# CTRL_MODULE_CORE register map
Vendor: Texas Instruments
Registers are 32-bit, access per field, reset 0x0 unless marked. A register's access mark holds for its fields unless they carry their own. Offsets are as the file gives them; [hi:lo] are bit positions; {n}, {i} and the like mark numbered series; 'fields as' and 'values as' point back to an identical list.

## CTRL_MODULE_CORE (part 10 of 12)
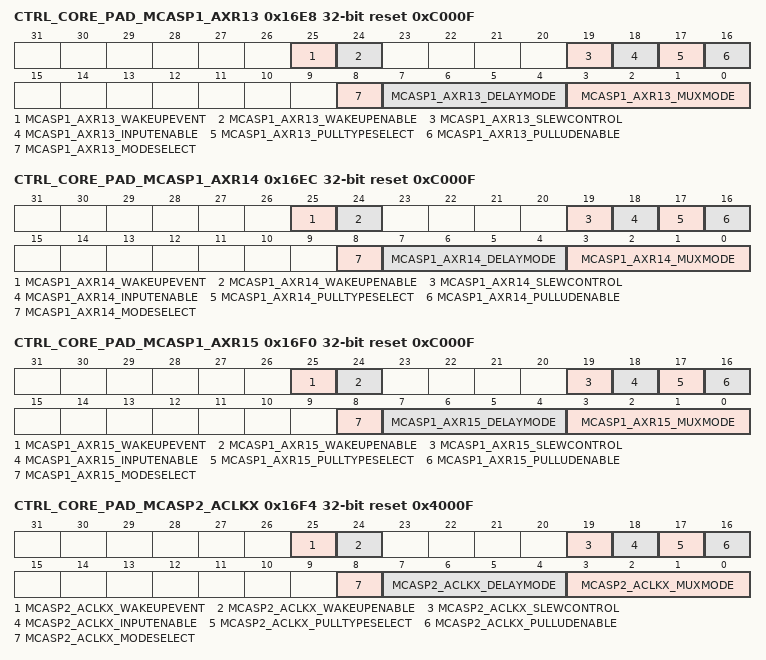
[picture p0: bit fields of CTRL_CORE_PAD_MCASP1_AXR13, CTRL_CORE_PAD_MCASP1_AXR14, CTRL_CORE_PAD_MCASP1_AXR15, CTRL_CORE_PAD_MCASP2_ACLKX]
0x16E8 CTRL_CORE_PAD_MCASP1_AXR13 reset 0xC000F
  [25] MCASP1_AXR13_WAKEUPEVENT ro
    0=NOWAKEUP (No wakeup event detected); 1=WAKEUP (Wakeup event detected)
  [24] MCASP1_AXR13_WAKEUPENABLE rw
    0=DISABLE (Wakeup is disabled); 1=ENABLE (Wakeup is enabled)
  [19] MCASP1_AXR13_SLEWCONTROL rw
    0=FAST_SLEW (Fast slew is selected); 1=SLOW_SLEW (Slow slew is selected)
  [18] MCASP1_AXR13_INPUTENABLE rw
    0=DISABLE (Receive mode is disabled); 1=ENABLE (Receive mode is enabled)
  [17] MCASP1_AXR13_PULLTYPESELECT rw
    0=PULL_DOWN (Pull Down is selected); 1=PULL_UP (Pull Up is selected)
  [16] MCASP1_AXR13_PULLUDENABLE rw
    0=ENABLE (Enables weak Pull Up/Down); 1=DISABLE (Disables weak Pull Up/Down)
  [8] MCASP1_AXR13_MODESELECT rw — Selects between the Default IO Timing Mode and a Virtual or Manual IO Timing Mode. Refer to the device Data Manual for definition of the required settings for a given mode of operation. When this bit is 0b1, a Virtual IO Timing Mode can be selected via the DELAYMODE field of this register, as described in, Virtual IO Timing Modes. Manual IO Timing Modes are selected via the procedure described in , Manual IO Timing Modes.
    0=MUX_MODE (Default IO Timing Mode is used); 1=DELAY_MODE (A Virtual or Manual IO Timing Mode is used)
  [7:4] MCASP1_AXR13_DELAYMODE rw — This bit field selects the Virtual Timing Mode used when the MODESELECT bit is set to 0b1. See, Virtual IO Timing Modes for details.
  [3:0] MCASP1_AXR13_MUXMODE rw
    0=MCASP1_AXR13; 1=MCASP7_AXR1; 7=VIN6A_D10; 10=TIMER10; 11=PR2_MII_MR0_CLK; 12=PR2_PRU1_GPI15; 13=PR2_PRU1_GPO15; 14=GPIO6_4; 15=DRIVER OFF
0x16EC CTRL_CORE_PAD_MCASP1_AXR14 reset 0xC000F
  [25] MCASP1_AXR14_WAKEUPEVENT ro
    values as CTRL_CORE_PAD_MCASP1_AXR13.MCASP1_AXR13_WAKEUPEVENT
  [24] MCASP1_AXR14_WAKEUPENABLE rw
    0=DISABLE (Wakeup is disabled); 1=ENABLE (Wakeup is enabled)
  [19] MCASP1_AXR14_SLEWCONTROL rw
    values as CTRL_CORE_PAD_MCASP1_AXR13.MCASP1_AXR13_SLEWCONTROL
  [18] MCASP1_AXR14_INPUTENABLE rw
    values as CTRL_CORE_PAD_MCASP1_AXR13.MCASP1_AXR13_INPUTENABLE
  [17] MCASP1_AXR14_PULLTYPESELECT rw
    values as CTRL_CORE_PAD_MCASP1_AXR13.MCASP1_AXR13_PULLTYPESELECT
  [16] MCASP1_AXR14_PULLUDENABLE rw
    values as CTRL_CORE_PAD_MCASP1_AXR13.MCASP1_AXR13_PULLUDENABLE
  [8] MCASP1_AXR14_MODESELECT rw — Selects between the Default IO Timing Mode and a Virtual or Manual IO Timing Mode. Refer to the device Data Manual for definition of the required settings for a given mode of operation. When this bit is 0b1, a Virtual IO Timing Mode can be selected via the DELAYMODE field of this register, as described in, Virtual IO Timing Modes. Manual IO Timing Modes are selected via the procedure described in , Manual IO Timing Modes.
    values as CTRL_CORE_PAD_MCASP1_AXR13.MCASP1_AXR13_MODESELECT
  [7:4] MCASP1_AXR14_DELAYMODE rw — This bit field selects the Virtual Timing Mode used when the MODESELECT bit is set to 0b1. See, Virtual IO Timing Modes for details.
  [3:0] MCASP1_AXR14_MUXMODE rw
    0=MCASP1_AXR14; 1=MCASP7_ACLKX; 2=MCASP7_ACLKR; 7=VIN6A_D9; 10=TIMER11; 11=PR2_MII0_RXDV; 12=PR2_PRU1_GPI16; 13=PR2_PRU1_GPO16; 14=GPIO6_5; 15=DRIVER OFF
0x16F0 CTRL_CORE_PAD_MCASP1_AXR15 reset 0xC000F
  [25] MCASP1_AXR15_WAKEUPEVENT ro
    values as CTRL_CORE_PAD_MCASP1_AXR13.MCASP1_AXR13_WAKEUPEVENT
  [24] MCASP1_AXR15_WAKEUPENABLE rw
    0=DISABLE (Wakeup is disabled); 1=ENABLE (Wakeup is enabled)
  [19] MCASP1_AXR15_SLEWCONTROL rw
    values as CTRL_CORE_PAD_MCASP1_AXR13.MCASP1_AXR13_SLEWCONTROL
  [18] MCASP1_AXR15_INPUTENABLE rw
    values as CTRL_CORE_PAD_MCASP1_AXR13.MCASP1_AXR13_INPUTENABLE
  [17] MCASP1_AXR15_PULLTYPESELECT rw
    values as CTRL_CORE_PAD_MCASP1_AXR13.MCASP1_AXR13_PULLTYPESELECT
  [16] MCASP1_AXR15_PULLUDENABLE rw
    values as CTRL_CORE_PAD_MCASP1_AXR13.MCASP1_AXR13_PULLUDENABLE
  [8] MCASP1_AXR15_MODESELECT rw — Selects between the Default IO Timing Mode and a Virtual or Manual IO Timing Mode. Refer to the device Data Manual for definition of the required settings for a given mode of operation. When this bit is 0b1, a Virtual IO Timing Mode can be selected via the DELAYMODE field of this register, as described in, Virtual IO Timing Modes. Manual IO Timing Modes are selected via the procedure described in , Manual IO Timing Modes.
    values as CTRL_CORE_PAD_MCASP1_AXR13.MCASP1_AXR13_MODESELECT
  [7:4] MCASP1_AXR15_DELAYMODE rw — This bit field selects the Virtual Timing Mode used when the MODESELECT bit is set to 0b1. See, Virtual IO Timing Modes for details.
  [3:0] MCASP1_AXR15_MUXMODE rw
    0=MCASP1_AXR15; 1=MCASP7_FSX; 2=MCASP7_FSR; 7=VIN6A_D8; 10=TIMER12; 11=PR2_MII0_RXD3; 12=PR2_PRU0_GPI20; 13=PR2_PRU0_GPO20; 14=GPIO6_6; 15=DRIVER OFF
0x16F4 CTRL_CORE_PAD_MCASP2_ACLKX reset 0x4000F
  [25] MCASP2_ACLKX_WAKEUPEVENT ro
    values as CTRL_CORE_PAD_MCASP1_AXR13.MCASP1_AXR13_WAKEUPEVENT
  [24] MCASP2_ACLKX_WAKEUPENABLE rw
    0=DISABLE (Wakeup is disabled); 1=ENABLE (Wakeup is enabled)
  [19] MCASP2_ACLKX_SLEWCONTROL rw
    values as CTRL_CORE_PAD_MCASP1_AXR13.MCASP1_AXR13_SLEWCONTROL
  [18] MCASP2_ACLKX_INPUTENABLE rw
    values as CTRL_CORE_PAD_MCASP1_AXR13.MCASP1_AXR13_INPUTENABLE
  [17] MCASP2_ACLKX_PULLTYPESELECT rw
    values as CTRL_CORE_PAD_MCASP1_AXR13.MCASP1_AXR13_PULLTYPESELECT
  [16] MCASP2_ACLKX_PULLUDENABLE rw
    values as CTRL_CORE_PAD_MCASP1_AXR13.MCASP1_AXR13_PULLUDENABLE
  [8] MCASP2_ACLKX_MODESELECT rw — Selects between the Default IO Timing Mode and a Virtual or Manual IO Timing Mode. Refer to the device Data Manual for definition of the required settings for a given mode of operation. When this bit is 0b1, a Virtual IO Timing Mode can be selected via the DELAYMODE field of this register, as described in, Virtual IO Timing Modes. Manual IO Timing Modes are selected via the procedure described in , Manual IO Timing Modes.
    values as CTRL_CORE_PAD_MCASP1_AXR13.MCASP1_AXR13_MODESELECT
  [7:4] MCASP2_ACLKX_DELAYMODE rw — This bit field selects the Virtual Timing Mode used when the MODESELECT bit is set to 0b1. See, Virtual IO Timing Modes for details.
  [3:0] MCASP2_ACLKX_MUXMODE rw
    0=MCASP2_ACLKX; 7=VIN6A_D7; 11=PR2_MII0_RXD2; 12=PR2_PRU0_GPI18; 13=PR2_PRU0_GPO18; 15=DRIVER OFF
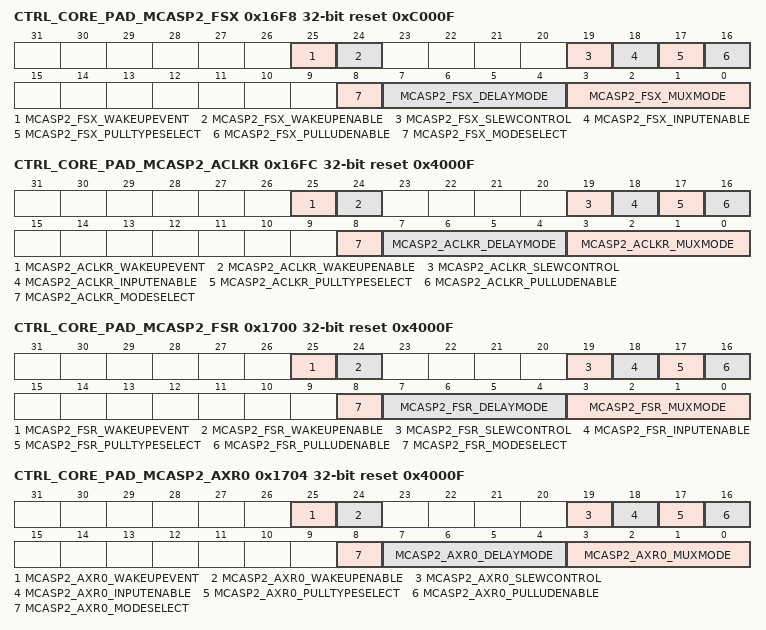
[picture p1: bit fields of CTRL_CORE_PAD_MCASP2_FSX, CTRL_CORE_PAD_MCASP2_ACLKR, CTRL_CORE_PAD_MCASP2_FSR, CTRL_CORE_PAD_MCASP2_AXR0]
0x16F8 CTRL_CORE_PAD_MCASP2_FSX reset 0xC000F
  [25] MCASP2_FSX_WAKEUPEVENT ro
    values as CTRL_CORE_PAD_MCASP1_AXR13.MCASP1_AXR13_WAKEUPEVENT
  [24] MCASP2_FSX_WAKEUPENABLE rw
    0=DISABLE (Wakeup is disabled); 1=ENABLE (Wakeup is enabled)
  [19] MCASP2_FSX_SLEWCONTROL rw
    values as CTRL_CORE_PAD_MCASP1_AXR13.MCASP1_AXR13_SLEWCONTROL
  [18] MCASP2_FSX_INPUTENABLE rw
    values as CTRL_CORE_PAD_MCASP1_AXR13.MCASP1_AXR13_INPUTENABLE
  [17] MCASP2_FSX_PULLTYPESELECT rw
    values as CTRL_CORE_PAD_MCASP1_AXR13.MCASP1_AXR13_PULLTYPESELECT
  [16] MCASP2_FSX_PULLUDENABLE rw
    values as CTRL_CORE_PAD_MCASP1_AXR13.MCASP1_AXR13_PULLUDENABLE
  [8] MCASP2_FSX_MODESELECT rw — Selects between the Default IO Timing Mode and a Virtual or Manual IO Timing Mode. Refer to the device Data Manual for definition of the required settings for a given mode of operation. When this bit is 0b1, a Virtual IO Timing Mode can be selected via the DELAYMODE field of this register, as described in, Virtual IO Timing Modes. Manual IO Timing Modes are selected via the procedure described in , Manual IO Timing Modes.
    values as CTRL_CORE_PAD_MCASP1_AXR13.MCASP1_AXR13_MODESELECT
  [7:4] MCASP2_FSX_DELAYMODE rw — This bit field selects the Virtual Timing Mode used when the MODESELECT bit is set to 0b1. See, Virtual IO Timing Modes for details.
  [3:0] MCASP2_FSX_MUXMODE rw
    0=MCASP2_FSX; 7=VIN6A_D6; 11=PR2_MII0_RXD1; 12=PR2_PRU0_GPI19; 13=PR2_PRU0_GPO19; 15=DRIVER OFF
0x16FC CTRL_CORE_PAD_MCASP2_ACLKR reset 0x4000F
  [25] MCASP2_ACLKR_WAKEUPEVENT ro
    values as CTRL_CORE_PAD_MCASP1_AXR13.MCASP1_AXR13_WAKEUPEVENT
  [24] MCASP2_ACLKR_WAKEUPENABLE rw
    0=DISABLE (Wakeup is disabled); 1=ENABLE (Wakeup is enabled)
  [19] MCASP2_ACLKR_SLEWCONTROL rw
    values as CTRL_CORE_PAD_MCASP1_AXR13.MCASP1_AXR13_SLEWCONTROL
  [18] MCASP2_ACLKR_INPUTENABLE rw
    values as CTRL_CORE_PAD_MCASP1_AXR13.MCASP1_AXR13_INPUTENABLE
  [17] MCASP2_ACLKR_PULLTYPESELECT rw
    values as CTRL_CORE_PAD_MCASP1_AXR13.MCASP1_AXR13_PULLTYPESELECT
  [16] MCASP2_ACLKR_PULLUDENABLE rw
    values as CTRL_CORE_PAD_MCASP1_AXR13.MCASP1_AXR13_PULLUDENABLE
  [8] MCASP2_ACLKR_MODESELECT rw — Selects between the Default IO Timing Mode and a Virtual or Manual IO Timing Mode. Refer to the device Data Manual for definition of the required settings for a given mode of operation. When this bit is 0b1, a Virtual IO Timing Mode can be selected via the DELAYMODE field of this register, as described in, Virtual IO Timing Modes. Manual IO Timing Modes are selected via the procedure described in , Manual IO Timing Modes.
    values as CTRL_CORE_PAD_MCASP1_AXR13.MCASP1_AXR13_MODESELECT
  [7:4] MCASP2_ACLKR_DELAYMODE rw — This bit field selects the Virtual Timing Mode used when the MODESELECT bit is set to 0b1. See, Virtual IO Timing Modes for details.
  [3:0] MCASP2_ACLKR_MUXMODE rw
    0=MCASP2_ACLKR; 1=MCASP8_AXR2; 6=VOUT2_D8; 8=VIN4A_D8; 15=DRIVER OFF
0x1700 CTRL_CORE_PAD_MCASP2_FSR reset 0x4000F
  [25] MCASP2_FSR_WAKEUPEVENT ro
    values as CTRL_CORE_PAD_MCASP1_AXR13.MCASP1_AXR13_WAKEUPEVENT
  [24] MCASP2_FSR_WAKEUPENABLE rw
    0=DISABLE (Wakeup is disabled); 1=ENABLE (Wakeup is enabled)
  [19] MCASP2_FSR_SLEWCONTROL rw
    values as CTRL_CORE_PAD_MCASP1_AXR13.MCASP1_AXR13_SLEWCONTROL
  [18] MCASP2_FSR_INPUTENABLE rw
    values as CTRL_CORE_PAD_MCASP1_AXR13.MCASP1_AXR13_INPUTENABLE
  [17] MCASP2_FSR_PULLTYPESELECT rw
    values as CTRL_CORE_PAD_MCASP1_AXR13.MCASP1_AXR13_PULLTYPESELECT
  [16] MCASP2_FSR_PULLUDENABLE rw
    values as CTRL_CORE_PAD_MCASP1_AXR13.MCASP1_AXR13_PULLUDENABLE
  [8] MCASP2_FSR_MODESELECT rw — Selects between the Default IO Timing Mode and a Virtual or Manual IO Timing Mode. Refer to the device Data Manual for definition of the required settings for a given mode of operation. When this bit is 0b1, a Virtual IO Timing Mode can be selected via the DELAYMODE field of this register, as described in, Virtual IO Timing Modes. Manual IO Timing Modes are selected via the procedure described in , Manual IO Timing Modes.
    values as CTRL_CORE_PAD_MCASP1_AXR13.MCASP1_AXR13_MODESELECT
  [7:4] MCASP2_FSR_DELAYMODE rw — This bit field selects the Virtual Timing Mode used when the MODESELECT bit is set to 0b1. See, Virtual IO Timing Modes for details.
  [3:0] MCASP2_FSR_MUXMODE rw
    0=MCASP2_FSR; 1=MCASP8_AXR3; 6=VOUT2_D9; 8=VIN4A_D9; 15=DRIVER OFF
0x1704 CTRL_CORE_PAD_MCASP2_AXR0 reset 0x4000F
  [25] MCASP2_AXR0_WAKEUPEVENT ro
    values as CTRL_CORE_PAD_MCASP1_AXR13.MCASP1_AXR13_WAKEUPEVENT
  [24] MCASP2_AXR0_WAKEUPENABLE rw
    0=DISABLE (Wakeup is disabled); 1=ENABLE (Wakeup is enabled)
  [19] MCASP2_AXR0_SLEWCONTROL rw
    values as CTRL_CORE_PAD_MCASP1_AXR13.MCASP1_AXR13_SLEWCONTROL
  [18] MCASP2_AXR0_INPUTENABLE rw
    values as CTRL_CORE_PAD_MCASP1_AXR13.MCASP1_AXR13_INPUTENABLE
  [17] MCASP2_AXR0_PULLTYPESELECT rw
    values as CTRL_CORE_PAD_MCASP1_AXR13.MCASP1_AXR13_PULLTYPESELECT
  [16] MCASP2_AXR0_PULLUDENABLE rw
    values as CTRL_CORE_PAD_MCASP1_AXR13.MCASP1_AXR13_PULLUDENABLE
  [8] MCASP2_AXR0_MODESELECT rw — Selects between the Default IO Timing Mode and a Virtual or Manual IO Timing Mode. Refer to the device Data Manual for definition of the required settings for a given mode of operation. When this bit is 0b1, a Virtual IO Timing Mode can be selected via the DELAYMODE field of this register, as described in, Virtual IO Timing Modes. Manual IO Timing Modes are selected via the procedure described in , Manual IO Timing Modes.
    values as CTRL_CORE_PAD_MCASP1_AXR13.MCASP1_AXR13_MODESELECT
  [7:4] MCASP2_AXR0_DELAYMODE rw — This bit field selects the Virtual Timing Mode used when the MODESELECT bit is set to 0b1. See, Virtual IO Timing Modes for details.
  [3:0] MCASP2_AXR0_MUXMODE rw
    0=MCASP2_AXR0; 6=VOUT2_D10; 8=VIN4A_D10; 15=DRIVER OFF
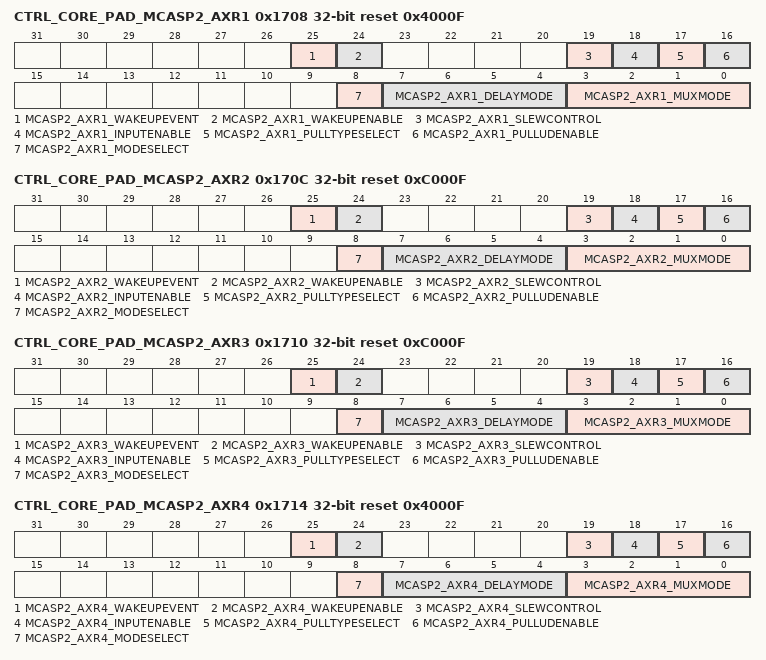
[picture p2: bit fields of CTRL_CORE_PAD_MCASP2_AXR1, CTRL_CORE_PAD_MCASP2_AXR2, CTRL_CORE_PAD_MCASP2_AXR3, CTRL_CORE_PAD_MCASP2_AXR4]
0x1708 CTRL_CORE_PAD_MCASP2_AXR1 reset 0x4000F
  [25] MCASP2_AXR1_WAKEUPEVENT ro
    values as CTRL_CORE_PAD_MCASP1_AXR13.MCASP1_AXR13_WAKEUPEVENT
  [24] MCASP2_AXR1_WAKEUPENABLE rw
    0=DISABLE (Wakeup is disabled); 1=ENABLE (Wakeup is enabled)
  [19] MCASP2_AXR1_SLEWCONTROL rw
    values as CTRL_CORE_PAD_MCASP1_AXR13.MCASP1_AXR13_SLEWCONTROL
  [18] MCASP2_AXR1_INPUTENABLE rw
    values as CTRL_CORE_PAD_MCASP1_AXR13.MCASP1_AXR13_INPUTENABLE
  [17] MCASP2_AXR1_PULLTYPESELECT rw
    values as CTRL_CORE_PAD_MCASP1_AXR13.MCASP1_AXR13_PULLTYPESELECT
  [16] MCASP2_AXR1_PULLUDENABLE rw
    values as CTRL_CORE_PAD_MCASP1_AXR13.MCASP1_AXR13_PULLUDENABLE
  [8] MCASP2_AXR1_MODESELECT rw — Selects between the Default IO Timing Mode and a Virtual or Manual IO Timing Mode. Refer to the device Data Manual for definition of the required settings for a given mode of operation. When this bit is 0b1, a Virtual IO Timing Mode can be selected via the DELAYMODE field of this register, as described in, Virtual IO Timing Modes. Manual IO Timing Modes are selected via the procedure described in , Manual IO Timing Modes.
    values as CTRL_CORE_PAD_MCASP1_AXR13.MCASP1_AXR13_MODESELECT
  [7:4] MCASP2_AXR1_DELAYMODE rw — This bit field selects the Virtual Timing Mode used when the MODESELECT bit is set to 0b1. See, Virtual IO Timing Modes for details.
  [3:0] MCASP2_AXR1_MUXMODE rw
    0=MCASP2_AXR1; 6=VOUT2_D11; 8=VIN4A_D11; 15=DRIVER OFF
0x170C CTRL_CORE_PAD_MCASP2_AXR2 reset 0xC000F
  [25] MCASP2_AXR2_WAKEUPEVENT ro
    values as CTRL_CORE_PAD_MCASP1_AXR13.MCASP1_AXR13_WAKEUPEVENT
  [24] MCASP2_AXR2_WAKEUPENABLE rw
    0=DISABLE (Wakeup is disabled); 1=ENABLE (Wakeup is enabled)
  [19] MCASP2_AXR2_SLEWCONTROL rw
    values as CTRL_CORE_PAD_MCASP1_AXR13.MCASP1_AXR13_SLEWCONTROL
  [18] MCASP2_AXR2_INPUTENABLE rw
    values as CTRL_CORE_PAD_MCASP1_AXR13.MCASP1_AXR13_INPUTENABLE
  [17] MCASP2_AXR2_PULLTYPESELECT rw
    values as CTRL_CORE_PAD_MCASP1_AXR13.MCASP1_AXR13_PULLTYPESELECT
  [16] MCASP2_AXR2_PULLUDENABLE rw
    values as CTRL_CORE_PAD_MCASP1_AXR13.MCASP1_AXR13_PULLUDENABLE
  [8] MCASP2_AXR2_MODESELECT rw — Selects between the Default IO Timing Mode and a Virtual or Manual IO Timing Mode. Refer to the device Data Manual for definition of the required settings for a given mode of operation. When this bit is 0b1, a Virtual IO Timing Mode can be selected via the DELAYMODE field of this register, as described in, Virtual IO Timing Modes. Manual IO Timing Modes are selected via the procedure described in , Manual IO Timing Modes.
    values as CTRL_CORE_PAD_MCASP1_AXR13.MCASP1_AXR13_MODESELECT
  [7:4] MCASP2_AXR2_DELAYMODE rw — This bit field selects the Virtual Timing Mode used when the MODESELECT bit is set to 0b1. See, Virtual IO Timing Modes for details.
  [3:0] MCASP2_AXR2_MUXMODE rw
    0=MCASP2_AXR2; 1=MCASP3_AXR2; 7=VIN6A_D5; 11=PR2_MII0_RXD0; 12=PR2_PRU0_GPI16; 13=PR2_PRU0_GPO16; 14=GPIO6_8; 15=DRIVER OFF
0x1710 CTRL_CORE_PAD_MCASP2_AXR3 reset 0xC000F
  [25] MCASP2_AXR3_WAKEUPEVENT ro
    values as CTRL_CORE_PAD_MCASP1_AXR13.MCASP1_AXR13_WAKEUPEVENT
  [24] MCASP2_AXR3_WAKEUPENABLE rw
    0=DISABLE (Wakeup is disabled); 1=ENABLE (Wakeup is enabled)
  [19] MCASP2_AXR3_SLEWCONTROL rw
    values as CTRL_CORE_PAD_MCASP1_AXR13.MCASP1_AXR13_SLEWCONTROL
  [18] MCASP2_AXR3_INPUTENABLE rw
    values as CTRL_CORE_PAD_MCASP1_AXR13.MCASP1_AXR13_INPUTENABLE
  [17] MCASP2_AXR3_PULLTYPESELECT rw
    values as CTRL_CORE_PAD_MCASP1_AXR13.MCASP1_AXR13_PULLTYPESELECT
  [16] MCASP2_AXR3_PULLUDENABLE rw
    values as CTRL_CORE_PAD_MCASP1_AXR13.MCASP1_AXR13_PULLUDENABLE
  [8] MCASP2_AXR3_MODESELECT rw — Selects between the Default IO Timing Mode and a Virtual or Manual IO Timing Mode. Refer to the device Data Manual for definition of the required settings for a given mode of operation. When this bit is 0b1, a Virtual IO Timing Mode can be selected via the DELAYMODE field of this register, as described in, Virtual IO Timing Modes. Manual IO Timing Modes are selected via the procedure described in , Manual IO Timing Modes.
    values as CTRL_CORE_PAD_MCASP1_AXR13.MCASP1_AXR13_MODESELECT
  [7:4] MCASP2_AXR3_DELAYMODE rw — This bit field selects the Virtual Timing Mode used when the MODESELECT bit is set to 0b1. See, Virtual IO Timing Modes for details.
  [3:0] MCASP2_AXR3_MUXMODE rw
    0=MCASP2_AXR3; 1=MCASP3_AXR3; 7=VIN6A_D4; 11=PR2_MII0_RXLINK; 12=PR2_PRU0_GPI17; 13=PR2_PRU0_GPO17; 14=GPIO6_9; 15=DRIVER OFF
0x1714 CTRL_CORE_PAD_MCASP2_AXR4 reset 0x4000F
  [25] MCASP2_AXR4_WAKEUPEVENT ro
    values as CTRL_CORE_PAD_MCASP1_AXR13.MCASP1_AXR13_WAKEUPEVENT
  [24] MCASP2_AXR4_WAKEUPENABLE rw
    0=DISABLE (Wakeup is disabled); 1=ENABLE (Wakeup is enabled)
  [19] MCASP2_AXR4_SLEWCONTROL rw
    values as CTRL_CORE_PAD_MCASP1_AXR13.MCASP1_AXR13_SLEWCONTROL
  [18] MCASP2_AXR4_INPUTENABLE rw
    values as CTRL_CORE_PAD_MCASP1_AXR13.MCASP1_AXR13_INPUTENABLE
  [17] MCASP2_AXR4_PULLTYPESELECT rw
    values as CTRL_CORE_PAD_MCASP1_AXR13.MCASP1_AXR13_PULLTYPESELECT
  [16] MCASP2_AXR4_PULLUDENABLE rw
    values as CTRL_CORE_PAD_MCASP1_AXR13.MCASP1_AXR13_PULLUDENABLE
  [8] MCASP2_AXR4_MODESELECT rw — Selects between the Default IO Timing Mode and a Virtual or Manual IO Timing Mode. Refer to the device Data Manual for definition of the required settings for a given mode of operation. When this bit is 0b1, a Virtual IO Timing Mode can be selected via the DELAYMODE field of this register, as described in, Virtual IO Timing Modes. Manual IO Timing Modes are selected via the procedure described in , Manual IO Timing Modes.
    values as CTRL_CORE_PAD_MCASP1_AXR13.MCASP1_AXR13_MODESELECT
  [7:4] MCASP2_AXR4_DELAYMODE rw — This bit field selects the Virtual Timing Mode used when the MODESELECT bit is set to 0b1. See, Virtual IO Timing Modes for details.
  [3:0] MCASP2_AXR4_MUXMODE rw
    0=MCASP2_AXR4; 1=MCASP8_AXR0; 6=VOUT2_D12; 8=VIN4A_D12; 14=GPIO1_4; 15=DRIVER OFF
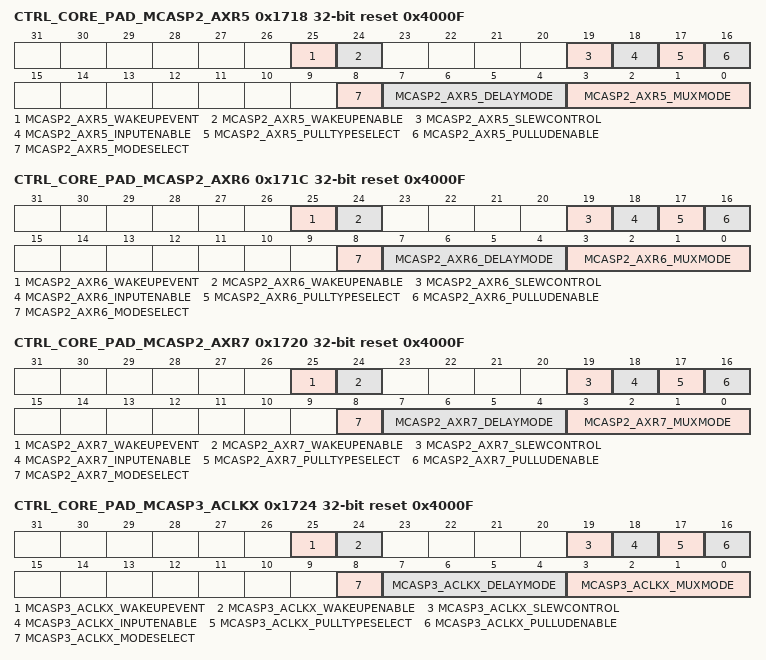
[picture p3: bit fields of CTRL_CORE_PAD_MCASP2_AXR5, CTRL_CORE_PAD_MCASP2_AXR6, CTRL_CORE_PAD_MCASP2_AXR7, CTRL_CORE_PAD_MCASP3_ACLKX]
0x1718 CTRL_CORE_PAD_MCASP2_AXR5 reset 0x4000F
  [25] MCASP2_AXR5_WAKEUPEVENT ro
    values as CTRL_CORE_PAD_MCASP1_AXR13.MCASP1_AXR13_WAKEUPEVENT
  [24] MCASP2_AXR5_WAKEUPENABLE rw
    0=DISABLE (Wakeup is disabled); 1=ENABLE (Wakeup is enabled)
  [19] MCASP2_AXR5_SLEWCONTROL rw
    values as CTRL_CORE_PAD_MCASP1_AXR13.MCASP1_AXR13_SLEWCONTROL
  [18] MCASP2_AXR5_INPUTENABLE rw
    values as CTRL_CORE_PAD_MCASP1_AXR13.MCASP1_AXR13_INPUTENABLE
  [17] MCASP2_AXR5_PULLTYPESELECT rw
    values as CTRL_CORE_PAD_MCASP1_AXR13.MCASP1_AXR13_PULLTYPESELECT
  [16] MCASP2_AXR5_PULLUDENABLE rw
    values as CTRL_CORE_PAD_MCASP1_AXR13.MCASP1_AXR13_PULLUDENABLE
  [8] MCASP2_AXR5_MODESELECT rw — Selects between the Default IO Timing Mode and a Virtual or Manual IO Timing Mode. Refer to the device Data Manual for definition of the required settings for a given mode of operation. When this bit is 0b1, a Virtual IO Timing Mode can be selected via the DELAYMODE field of this register, as described in, Virtual IO Timing Modes. Manual IO Timing Modes are selected via the procedure described in , Manual IO Timing Modes.
    values as CTRL_CORE_PAD_MCASP1_AXR13.MCASP1_AXR13_MODESELECT
  [7:4] MCASP2_AXR5_DELAYMODE rw — This bit field selects the Virtual Timing Mode used when the MODESELECT bit is set to 0b1. See, Virtual IO Timing Modes for details.
  [3:0] MCASP2_AXR5_MUXMODE rw
    0=MCASP2_AXR5; 1=MCASP8_AXR1; 6=VOUT2_D13; 8=VIN4A_D13; 14=GPIO6_7; 15=DRIVER OFF
0x171C CTRL_CORE_PAD_MCASP2_AXR6 reset 0x4000F
  [25] MCASP2_AXR6_WAKEUPEVENT ro
    values as CTRL_CORE_PAD_MCASP1_AXR13.MCASP1_AXR13_WAKEUPEVENT
  [24] MCASP2_AXR6_WAKEUPENABLE rw
    0=DISABLE (Wakeup is disabled); 1=ENABLE (Wakeup is enabled)
  [19] MCASP2_AXR6_SLEWCONTROL rw
    values as CTRL_CORE_PAD_MCASP1_AXR13.MCASP1_AXR13_SLEWCONTROL
  [18] MCASP2_AXR6_INPUTENABLE rw
    values as CTRL_CORE_PAD_MCASP1_AXR13.MCASP1_AXR13_INPUTENABLE
  [17] MCASP2_AXR6_PULLTYPESELECT rw
    values as CTRL_CORE_PAD_MCASP1_AXR13.MCASP1_AXR13_PULLTYPESELECT
  [16] MCASP2_AXR6_PULLUDENABLE rw
    values as CTRL_CORE_PAD_MCASP1_AXR13.MCASP1_AXR13_PULLUDENABLE
  [8] MCASP2_AXR6_MODESELECT rw — Selects between the Default IO Timing Mode and a Virtual or Manual IO Timing Mode. Refer to the device Data Manual for definition of the required settings for a given mode of operation. When this bit is 0b1, a Virtual IO Timing Mode can be selected via the DELAYMODE field of this register, as described in, Virtual IO Timing Modes. Manual IO Timing Modes are selected via the procedure described in , Manual IO Timing Modes.
    values as CTRL_CORE_PAD_MCASP1_AXR13.MCASP1_AXR13_MODESELECT
  [7:4] MCASP2_AXR6_DELAYMODE rw — This bit field selects the Virtual Timing Mode used when the MODESELECT bit is set to 0b1. See, Virtual IO Timing Modes for details.
  [3:0] MCASP2_AXR6_MUXMODE rw
    0=MCASP2_AXR6; 1=MCASP8_ACLKX; 2=MCASP8_ACLKR; 6=VOUT2_D14; 8=VIN4A_D14; 14=GPIO2_29; 15=DRIVER OFF
0x1720 CTRL_CORE_PAD_MCASP2_AXR7 reset 0x4000F
  [25] MCASP2_AXR7_WAKEUPEVENT ro
    values as CTRL_CORE_PAD_MCASP1_AXR13.MCASP1_AXR13_WAKEUPEVENT
  [24] MCASP2_AXR7_WAKEUPENABLE rw
    0=DISABLE (Wakeup is disabled); 1=ENABLE (Wakeup is enabled)
  [19] MCASP2_AXR7_SLEWCONTROL rw
    values as CTRL_CORE_PAD_MCASP1_AXR13.MCASP1_AXR13_SLEWCONTROL
  [18] MCASP2_AXR7_INPUTENABLE rw
    values as CTRL_CORE_PAD_MCASP1_AXR13.MCASP1_AXR13_INPUTENABLE
  [17] MCASP2_AXR7_PULLTYPESELECT rw
    values as CTRL_CORE_PAD_MCASP1_AXR13.MCASP1_AXR13_PULLTYPESELECT
  [16] MCASP2_AXR7_PULLUDENABLE rw
    values as CTRL_CORE_PAD_MCASP1_AXR13.MCASP1_AXR13_PULLUDENABLE
  [8] MCASP2_AXR7_MODESELECT rw — Selects between the Default IO Timing Mode and a Virtual or Manual IO Timing Mode. Refer to the device Data Manual for definition of the required settings for a given mode of operation. When this bit is 0b1, a Virtual IO Timing Mode can be selected via the DELAYMODE field of this register, as described in, Virtual IO Timing Modes. Manual IO Timing Modes are selected via the procedure described in , Manual IO Timing Modes.
    values as CTRL_CORE_PAD_MCASP1_AXR13.MCASP1_AXR13_MODESELECT
  [7:4] MCASP2_AXR7_DELAYMODE rw — This bit field selects the Virtual Timing Mode used when the MODESELECT bit is set to 0b1. See, Virtual IO Timing Modes for details.
  [3:0] MCASP2_AXR7_MUXMODE rw
    0=MCASP2_AXR7; 1=MCASP8_FSX; 2=MCASP8_FSR; 6=VOUT2_D15; 8=VIN4A_D15; 14=GPIO1_5; 15=DRIVER OFF
0x1724 CTRL_CORE_PAD_MCASP3_ACLKX reset 0x4000F
  [25] MCASP3_ACLKX_WAKEUPEVENT ro
    values as CTRL_CORE_PAD_MCASP1_AXR13.MCASP1_AXR13_WAKEUPEVENT
  [24] MCASP3_ACLKX_WAKEUPENABLE rw
    0=DISABLE (Wakeup is disabled); 1=ENABLE (Wakeup is enabled)
  [19] MCASP3_ACLKX_SLEWCONTROL rw
    values as CTRL_CORE_PAD_MCASP1_AXR13.MCASP1_AXR13_SLEWCONTROL
  [18] MCASP3_ACLKX_INPUTENABLE rw
    values as CTRL_CORE_PAD_MCASP1_AXR13.MCASP1_AXR13_INPUTENABLE
  [17] MCASP3_ACLKX_PULLTYPESELECT rw
    values as CTRL_CORE_PAD_MCASP1_AXR13.MCASP1_AXR13_PULLTYPESELECT
  [16] MCASP3_ACLKX_PULLUDENABLE rw
    values as CTRL_CORE_PAD_MCASP1_AXR13.MCASP1_AXR13_PULLUDENABLE
  [8] MCASP3_ACLKX_MODESELECT rw — Selects between the Default IO Timing Mode and a Virtual or Manual IO Timing Mode. Refer to the device Data Manual for definition of the required settings for a given mode of operation. When this bit is 0b1, a Virtual IO Timing Mode can be selected via the DELAYMODE field of this register, as described in, Virtual IO Timing Modes. Manual IO Timing Modes are selected via the procedure described in , Manual IO Timing Modes.
    values as CTRL_CORE_PAD_MCASP1_AXR13.MCASP1_AXR13_MODESELECT
  [7:4] MCASP3_ACLKX_DELAYMODE rw — This bit field selects the Virtual Timing Mode used when the MODESELECT bit is set to 0b1. See, Virtual IO Timing Modes for details.
  [3:0] MCASP3_ACLKX_MUXMODE rw
    0=MCASP3_ACLKX; 1=MCASP3_ACLKR; 2=MCASP2_AXR12; 3=UART7_RXD; 7=VIN6A_D3; 11=PR2_MII0_CRS; 12=PR2_PRU0_GPI12; 13=PR2_PRU0_GPO12; 14=GPIO5_13; 15=DRIVER OFF
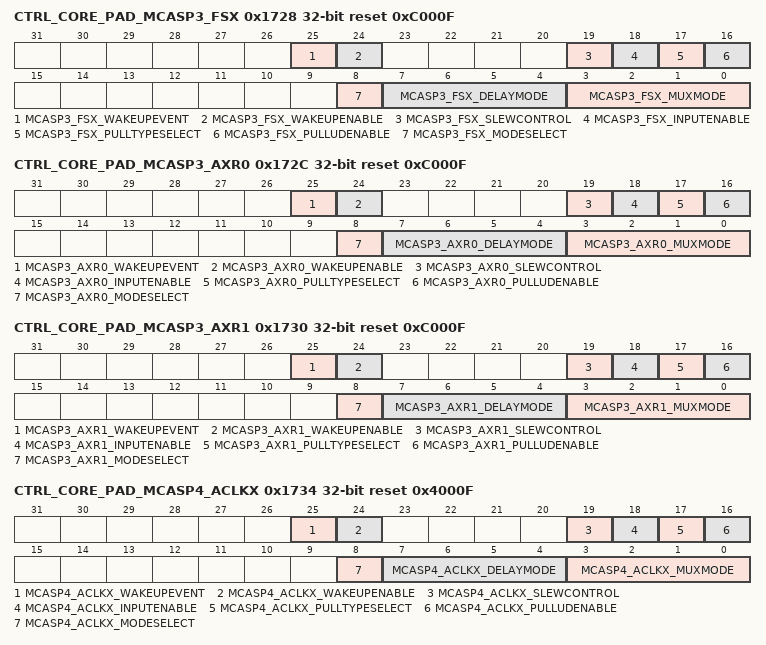
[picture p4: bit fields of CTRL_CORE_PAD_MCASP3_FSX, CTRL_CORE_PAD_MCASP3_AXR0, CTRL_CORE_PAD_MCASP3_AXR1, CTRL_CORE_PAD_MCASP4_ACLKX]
0x1728 CTRL_CORE_PAD_MCASP3_FSX reset 0xC000F
  [25] MCASP3_FSX_WAKEUPEVENT ro
    values as CTRL_CORE_PAD_MCASP1_AXR13.MCASP1_AXR13_WAKEUPEVENT
  [24] MCASP3_FSX_WAKEUPENABLE rw
    0=DISABLE (Wakeup is disabled); 1=ENABLE (Wakeup is enabled)
  [19] MCASP3_FSX_SLEWCONTROL rw
    values as CTRL_CORE_PAD_MCASP1_AXR13.MCASP1_AXR13_SLEWCONTROL
  [18] MCASP3_FSX_INPUTENABLE rw
    values as CTRL_CORE_PAD_MCASP1_AXR13.MCASP1_AXR13_INPUTENABLE
  [17] MCASP3_FSX_PULLTYPESELECT rw
    values as CTRL_CORE_PAD_MCASP1_AXR13.MCASP1_AXR13_PULLTYPESELECT
  [16] MCASP3_FSX_PULLUDENABLE rw
    values as CTRL_CORE_PAD_MCASP1_AXR13.MCASP1_AXR13_PULLUDENABLE
  [8] MCASP3_FSX_MODESELECT rw — Selects between the Default IO Timing Mode and a Virtual or Manual IO Timing Mode. Refer to the device Data Manual for definition of the required settings for a given mode of operation. When this bit is 0b1, a Virtual IO Timing Mode can be selected via the DELAYMODE field of this register, as described in, Virtual IO Timing Modes. Manual IO Timing Modes are selected via the procedure described in , Manual IO Timing Modes.
    values as CTRL_CORE_PAD_MCASP1_AXR13.MCASP1_AXR13_MODESELECT
  [7:4] MCASP3_FSX_DELAYMODE rw — This bit field selects the Virtual Timing Mode used when the MODESELECT bit is set to 0b1. See, Virtual IO Timing Modes for details.
  [3:0] MCASP3_FSX_MUXMODE rw
    0=MCASP3_FSX; 1=MCASP3_FSR; 2=MCASP2_AXR13; 3=UART7_TXD; 7=VIN6A_D2; 11=PR2_MII0_COL; 12=PR2_PRU0_GPI13; 13=PR2_PRU0_GPO13; 14=GPIO5_14; 15=DRIVER OFF
0x172C CTRL_CORE_PAD_MCASP3_AXR0 reset 0xC000F
  [25] MCASP3_AXR0_WAKEUPEVENT ro
    values as CTRL_CORE_PAD_MCASP1_AXR13.MCASP1_AXR13_WAKEUPEVENT
  [24] MCASP3_AXR0_WAKEUPENABLE rw
    0=DISABLE (Wakeup is disabled); 1=ENABLE (Wakeup is enabled)
  [19] MCASP3_AXR0_SLEWCONTROL rw
    values as CTRL_CORE_PAD_MCASP1_AXR13.MCASP1_AXR13_SLEWCONTROL
  [18] MCASP3_AXR0_INPUTENABLE rw
    values as CTRL_CORE_PAD_MCASP1_AXR13.MCASP1_AXR13_INPUTENABLE
  [17] MCASP3_AXR0_PULLTYPESELECT rw
    values as CTRL_CORE_PAD_MCASP1_AXR13.MCASP1_AXR13_PULLTYPESELECT
  [16] MCASP3_AXR0_PULLUDENABLE rw
    values as CTRL_CORE_PAD_MCASP1_AXR13.MCASP1_AXR13_PULLUDENABLE
  [8] MCASP3_AXR0_MODESELECT rw — Selects between the Default IO Timing Mode and a Virtual or Manual IO Timing Mode. Refer to the device Data Manual for definition of the required settings for a given mode of operation. When this bit is 0b1, a Virtual IO Timing Mode can be selected via the DELAYMODE field of this register, as described in, Virtual IO Timing Modes. Manual IO Timing Modes are selected via the procedure described in , Manual IO Timing Modes.
    values as CTRL_CORE_PAD_MCASP1_AXR13.MCASP1_AXR13_MODESELECT
  [7:4] MCASP3_AXR0_DELAYMODE rw — This bit field selects the Virtual Timing Mode used when the MODESELECT bit is set to 0b1. See, Virtual IO Timing Modes for details.
  [3:0] MCASP3_AXR0_MUXMODE rw
    0=MCASP3_AXR0; 2=MCASP2_AXR14; 3=UART7_CTSN; 4=UART5_RXD; 7=VIN6A_D1; 11=PR2_MII1_RXER; 12=PR2_PRU0_GPI14; 13=PR2_PRU0_GPO14; 15=DRIVER OFF
0x1730 CTRL_CORE_PAD_MCASP3_AXR1 reset 0xC000F
  [25] MCASP3_AXR1_WAKEUPEVENT ro
    values as CTRL_CORE_PAD_MCASP1_AXR13.MCASP1_AXR13_WAKEUPEVENT
  [24] MCASP3_AXR1_WAKEUPENABLE rw
    0=DISABLE (Wakeup is disabled); 1=ENABLE (Wakeup is enabled)
  [19] MCASP3_AXR1_SLEWCONTROL rw
    values as CTRL_CORE_PAD_MCASP1_AXR13.MCASP1_AXR13_SLEWCONTROL
  [18] MCASP3_AXR1_INPUTENABLE rw
    values as CTRL_CORE_PAD_MCASP1_AXR13.MCASP1_AXR13_INPUTENABLE
  [17] MCASP3_AXR1_PULLTYPESELECT rw
    values as CTRL_CORE_PAD_MCASP1_AXR13.MCASP1_AXR13_PULLTYPESELECT
  [16] MCASP3_AXR1_PULLUDENABLE rw
    values as CTRL_CORE_PAD_MCASP1_AXR13.MCASP1_AXR13_PULLUDENABLE
  [8] MCASP3_AXR1_MODESELECT rw — Selects between the Default IO Timing Mode and a Virtual or Manual IO Timing Mode. Refer to the device Data Manual for definition of the required settings for a given mode of operation. When this bit is 0b1, a Virtual IO Timing Mode can be selected via the DELAYMODE field of this register, as described in, Virtual IO Timing Modes. Manual IO Timing Modes are selected via the procedure described in , Manual IO Timing Modes.
    values as CTRL_CORE_PAD_MCASP1_AXR13.MCASP1_AXR13_MODESELECT
  [7:4] MCASP3_AXR1_DELAYMODE rw — This bit field selects the Virtual Timing Mode used when the MODESELECT bit is set to 0b1. See, Virtual IO Timing Modes for details.
  [3:0] MCASP3_AXR1_MUXMODE rw
    0=MCASP3_AXR1; 2=MCASP2_AXR15; 3=UART7_RTSN; 4=UART5_TXD; 7=VIN6A_D0; 9=VIN5A_FLD0; 11=PR2_MII1_RXLINK; 12=PR2_PRU0_GPI15; 13=PR2_PRU0_GPO15; 15=DRIVER OFF
0x1734 CTRL_CORE_PAD_MCASP4_ACLKX reset 0x4000F
  [25] MCASP4_ACLKX_WAKEUPEVENT ro
    values as CTRL_CORE_PAD_MCASP1_AXR13.MCASP1_AXR13_WAKEUPEVENT
  [24] MCASP4_ACLKX_WAKEUPENABLE rw
    0=DISABLE (Wakeup is disabled); 1=ENABLE (Wakeup is enabled)
  [19] MCASP4_ACLKX_SLEWCONTROL rw
    values as CTRL_CORE_PAD_MCASP1_AXR13.MCASP1_AXR13_SLEWCONTROL
  [18] MCASP4_ACLKX_INPUTENABLE rw
    values as CTRL_CORE_PAD_MCASP1_AXR13.MCASP1_AXR13_INPUTENABLE
  [17] MCASP4_ACLKX_PULLTYPESELECT rw
    values as CTRL_CORE_PAD_MCASP1_AXR13.MCASP1_AXR13_PULLTYPESELECT
  [16] MCASP4_ACLKX_PULLUDENABLE rw
    values as CTRL_CORE_PAD_MCASP1_AXR13.MCASP1_AXR13_PULLUDENABLE
  [8] MCASP4_ACLKX_MODESELECT rw — Selects between the Default IO Timing Mode and a Virtual or Manual IO Timing Mode. Refer to the device Data Manual for definition of the required settings for a given mode of operation. When this bit is 0b1, a Virtual IO Timing Mode can be selected via the DELAYMODE field of this register, as described in, Virtual IO Timing Modes. Manual IO Timing Modes are selected via the procedure described in , Manual IO Timing Modes.
    values as CTRL_CORE_PAD_MCASP1_AXR13.MCASP1_AXR13_MODESELECT
  [7:4] MCASP4_ACLKX_DELAYMODE rw — This bit field selects the Virtual Timing Mode used when the MODESELECT bit is set to 0b1. See, Virtual IO Timing Modes for details.
  [3:0] MCASP4_ACLKX_MUXMODE rw
    0=MCASP4_ACLKX; 1=MCASP4_ACLKR; 2=SPI3_SCLK; 3=UART8_RXD; 4=I2C4_SDA; 6=VOUT2_D16; 8=VIN4A_D16; 9=VIN5A_D15; 15=DRIVER OFF
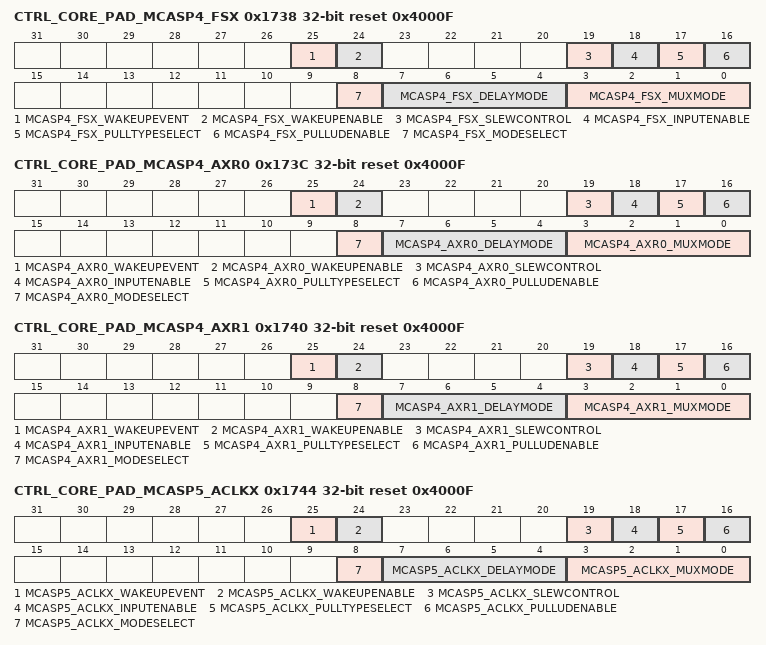
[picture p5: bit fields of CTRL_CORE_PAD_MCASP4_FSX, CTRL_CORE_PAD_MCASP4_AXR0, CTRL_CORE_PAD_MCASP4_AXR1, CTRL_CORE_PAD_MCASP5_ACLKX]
0x1738 CTRL_CORE_PAD_MCASP4_FSX reset 0x4000F
  [25] MCASP4_FSX_WAKEUPEVENT ro
    values as CTRL_CORE_PAD_MCASP1_AXR13.MCASP1_AXR13_WAKEUPEVENT
  [24] MCASP4_FSX_WAKEUPENABLE rw
    0=DISABLE (Wakeup is disabled); 1=ENABLE (Wakeup is enabled)
  [19] MCASP4_FSX_SLEWCONTROL rw
    values as CTRL_CORE_PAD_MCASP1_AXR13.MCASP1_AXR13_SLEWCONTROL
  [18] MCASP4_FSX_INPUTENABLE rw
    values as CTRL_CORE_PAD_MCASP1_AXR13.MCASP1_AXR13_INPUTENABLE
  [17] MCASP4_FSX_PULLTYPESELECT rw
    values as CTRL_CORE_PAD_MCASP1_AXR13.MCASP1_AXR13_PULLTYPESELECT
  [16] MCASP4_FSX_PULLUDENABLE rw
    values as CTRL_CORE_PAD_MCASP1_AXR13.MCASP1_AXR13_PULLUDENABLE
  [8] MCASP4_FSX_MODESELECT rw — Selects between the Default IO Timing Mode and a Virtual or Manual IO Timing Mode. Refer to the device Data Manual for definition of the required settings for a given mode of operation. When this bit is 0b1, a Virtual IO Timing Mode can be selected via the DELAYMODE field of this register, as described in, Virtual IO Timing Modes. Manual IO Timing Modes are selected via the procedure described in , Manual IO Timing Modes.
    values as CTRL_CORE_PAD_MCASP1_AXR13.MCASP1_AXR13_MODESELECT
  [7:4] MCASP4_FSX_DELAYMODE rw — This bit field selects the Virtual Timing Mode used when the MODESELECT bit is set to 0b1. See, Virtual IO Timing Modes for details.
  [3:0] MCASP4_FSX_MUXMODE rw
    0=MCASP4_FSX; 1=MCASP4_FSR; 2=SPI3_D1; 3=UART8_TXD; 4=I2C4_SCL; 6=VOUT2_D17; 8=VIN4A_D17; 9=VIN5A_D14; 15=DRIVER OFF
0x173C CTRL_CORE_PAD_MCASP4_AXR0 reset 0x4000F
  [25] MCASP4_AXR0_WAKEUPEVENT ro
    values as CTRL_CORE_PAD_MCASP1_AXR13.MCASP1_AXR13_WAKEUPEVENT
  [24] MCASP4_AXR0_WAKEUPENABLE rw
    0=DISABLE (Wakeup is disabled); 1=ENABLE (Wakeup is enabled)
  [19] MCASP4_AXR0_SLEWCONTROL rw
    values as CTRL_CORE_PAD_MCASP1_AXR13.MCASP1_AXR13_SLEWCONTROL
  [18] MCASP4_AXR0_INPUTENABLE rw
    values as CTRL_CORE_PAD_MCASP1_AXR13.MCASP1_AXR13_INPUTENABLE
  [17] MCASP4_AXR0_PULLTYPESELECT rw
    values as CTRL_CORE_PAD_MCASP1_AXR13.MCASP1_AXR13_PULLTYPESELECT
  [16] MCASP4_AXR0_PULLUDENABLE rw
    values as CTRL_CORE_PAD_MCASP1_AXR13.MCASP1_AXR13_PULLUDENABLE
  [8] MCASP4_AXR0_MODESELECT rw — Selects between the Default IO Timing Mode and a Virtual or Manual IO Timing Mode. Refer to the device Data Manual for definition of the required settings for a given mode of operation. When this bit is 0b1, a Virtual IO Timing Mode can be selected via the DELAYMODE field of this register, as described in, Virtual IO Timing Modes. Manual IO Timing Modes are selected via the procedure described in , Manual IO Timing Modes.
    values as CTRL_CORE_PAD_MCASP1_AXR13.MCASP1_AXR13_MODESELECT
  [7:4] MCASP4_AXR0_DELAYMODE rw — This bit field selects the Virtual Timing Mode used when the MODESELECT bit is set to 0b1. See, Virtual IO Timing Modes for details.
  [3:0] MCASP4_AXR0_MUXMODE rw
    0=MCASP4_AXR0; 2=SPI3_D0; 3=UART8_CTSN; 4=UART4_RXD; 6=VOUT2_D18; 8=VIN4A_D18; 9=VIN5A_D13; 15=DRIVER OFF
0x1740 CTRL_CORE_PAD_MCASP4_AXR1 reset 0x4000F
  [25] MCASP4_AXR1_WAKEUPEVENT ro
    values as CTRL_CORE_PAD_MCASP1_AXR13.MCASP1_AXR13_WAKEUPEVENT
  [24] MCASP4_AXR1_WAKEUPENABLE rw
    0=DISABLE (Wakeup is disabled); 1=ENABLE (Wakeup is enabled)
  [19] MCASP4_AXR1_SLEWCONTROL rw
    values as CTRL_CORE_PAD_MCASP1_AXR13.MCASP1_AXR13_SLEWCONTROL
  [18] MCASP4_AXR1_INPUTENABLE rw
    values as CTRL_CORE_PAD_MCASP1_AXR13.MCASP1_AXR13_INPUTENABLE
  [17] MCASP4_AXR1_PULLTYPESELECT rw
    values as CTRL_CORE_PAD_MCASP1_AXR13.MCASP1_AXR13_PULLTYPESELECT
  [16] MCASP4_AXR1_PULLUDENABLE rw
    values as CTRL_CORE_PAD_MCASP1_AXR13.MCASP1_AXR13_PULLUDENABLE
  [8] MCASP4_AXR1_MODESELECT rw — Selects between the Default IO Timing Mode and a Virtual or Manual IO Timing Mode. Refer to the device Data Manual for definition of the required settings for a given mode of operation. When this bit is 0b1, a Virtual IO Timing Mode can be selected via the DELAYMODE field of this register, as described in, Virtual IO Timing Modes. Manual IO Timing Modes are selected via the procedure described in , Manual IO Timing Modes.
    values as CTRL_CORE_PAD_MCASP1_AXR13.MCASP1_AXR13_MODESELECT
  [7:4] MCASP4_AXR1_DELAYMODE rw — This bit field selects the Virtual Timing Mode used when the MODESELECT bit is set to 0b1. See, Virtual IO Timing Modes for details.
  [3:0] MCASP4_AXR1_MUXMODE rw
    0=MCASP4_AXR1; 2=SPI3_CS0; 3=UART8_RTSN; 4=UART4_TXD; 6=VOUT2_D19; 8=VIN4A_D19; 9=VIN5A_D12; 12=PR2_PRU1_GPI0; 13=PR2_PRU1_GPO0; 15=DRIVER OFF
0x1744 CTRL_CORE_PAD_MCASP5_ACLKX reset 0x4000F
  [25] MCASP5_ACLKX_WAKEUPEVENT ro
    values as CTRL_CORE_PAD_MCASP1_AXR13.MCASP1_AXR13_WAKEUPEVENT
  [24] MCASP5_ACLKX_WAKEUPENABLE rw
    0=DISABLE (Wakeup is disabled); 1=ENABLE (Wakeup is enabled)
  [19] MCASP5_ACLKX_SLEWCONTROL rw
    values as CTRL_CORE_PAD_MCASP1_AXR13.MCASP1_AXR13_SLEWCONTROL
  [18] MCASP5_ACLKX_INPUTENABLE rw
    values as CTRL_CORE_PAD_MCASP1_AXR13.MCASP1_AXR13_INPUTENABLE
  [17] MCASP5_ACLKX_PULLTYPESELECT rw
    values as CTRL_CORE_PAD_MCASP1_AXR13.MCASP1_AXR13_PULLTYPESELECT
  [16] MCASP5_ACLKX_PULLUDENABLE rw
    values as CTRL_CORE_PAD_MCASP1_AXR13.MCASP1_AXR13_PULLUDENABLE
  [8] MCASP5_ACLKX_MODESELECT rw — Selects between the Default IO Timing Mode and a Virtual or Manual IO Timing Mode. Refer to the device Data Manual for definition of the required settings for a given mode of operation. When this bit is 0b1, a Virtual IO Timing Mode can be selected via the DELAYMODE field of this register, as described in, Virtual IO Timing Modes. Manual IO Timing Modes are selected via the procedure described in , Manual IO Timing Modes.
    values as CTRL_CORE_PAD_MCASP1_AXR13.MCASP1_AXR13_MODESELECT
  [7:4] MCASP5_ACLKX_DELAYMODE rw — This bit field selects the Virtual Timing Mode used when the MODESELECT bit is set to 0b1. See, Virtual IO Timing Modes for details.
  [3:0] MCASP5_ACLKX_MUXMODE rw
    0=MCASP5_ACLKX; 1=MCASP5_ACLKR; 2=SPI4_SCLK; 3=UART9_RXD; 4=I2C5_SDA; 6=VOUT2_D20; 8=VIN4A_D20; 9=VIN5A_D11; 12=PR2_PRU1_GPI1; 13=PR2_PRU1_GPO1; 15=DRIVER OFF
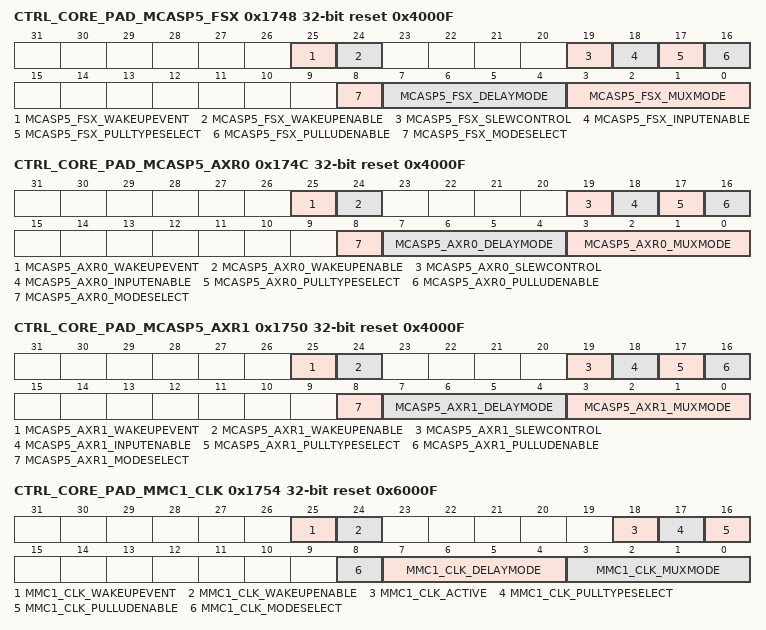
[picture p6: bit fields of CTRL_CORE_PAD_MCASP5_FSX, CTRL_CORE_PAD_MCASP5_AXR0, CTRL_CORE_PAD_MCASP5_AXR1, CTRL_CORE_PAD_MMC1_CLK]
0x1748 CTRL_CORE_PAD_MCASP5_FSX reset 0x4000F
  [25] MCASP5_FSX_WAKEUPEVENT ro
    values as CTRL_CORE_PAD_MCASP1_AXR13.MCASP1_AXR13_WAKEUPEVENT
  [24] MCASP5_FSX_WAKEUPENABLE rw
    0=DISABLE (Wakeup is disabled); 1=ENABLE (Wakeup is enabled)
  [19] MCASP5_FSX_SLEWCONTROL rw
    values as CTRL_CORE_PAD_MCASP1_AXR13.MCASP1_AXR13_SLEWCONTROL
  [18] MCASP5_FSX_INPUTENABLE rw
    values as CTRL_CORE_PAD_MCASP1_AXR13.MCASP1_AXR13_INPUTENABLE
  [17] MCASP5_FSX_PULLTYPESELECT rw
    values as CTRL_CORE_PAD_MCASP1_AXR13.MCASP1_AXR13_PULLTYPESELECT
  [16] MCASP5_FSX_PULLUDENABLE rw
    values as CTRL_CORE_PAD_MCASP1_AXR13.MCASP1_AXR13_PULLUDENABLE
  [8] MCASP5_FSX_MODESELECT rw — Selects between the Default IO Timing Mode and a Virtual or Manual IO Timing Mode. Refer to the device Data Manual for definition of the required settings for a given mode of operation. When this bit is 0b1, a Virtual IO Timing Mode can be selected via the DELAYMODE field of this register, as described in, Virtual IO Timing Modes. Manual IO Timing Modes are selected via the procedure described in , Manual IO Timing Modes.
    values as CTRL_CORE_PAD_MCASP1_AXR13.MCASP1_AXR13_MODESELECT
  [7:4] MCASP5_FSX_DELAYMODE rw — This bit field selects the Virtual Timing Mode used when the MODESELECT bit is set to 0b1. See, Virtual IO Timing Modes for details.
  [3:0] MCASP5_FSX_MUXMODE rw
    0=MCASP5_FSX; 1=MCASP5_FSR; 2=SPI4_D1; 3=UART9_TXD; 4=I2C5_SCL; 6=VOUT2_D21; 8=VIN4A_D21; 9=VIN5A_D10; 12=PR2_PRU1_GPI2; 13=PR2_PRU1_GPO2; 15=DRIVER OFF
0x174C CTRL_CORE_PAD_MCASP5_AXR0 reset 0x4000F
  [25] MCASP5_AXR0_WAKEUPEVENT ro
    values as CTRL_CORE_PAD_MCASP1_AXR13.MCASP1_AXR13_WAKEUPEVENT
  [24] MCASP5_AXR0_WAKEUPENABLE rw
    0=DISABLE (Wakeup is disabled); 1=ENABLE (Wakeup is enabled)
  [19] MCASP5_AXR0_SLEWCONTROL rw
    values as CTRL_CORE_PAD_MCASP1_AXR13.MCASP1_AXR13_SLEWCONTROL
  [18] MCASP5_AXR0_INPUTENABLE rw
    values as CTRL_CORE_PAD_MCASP1_AXR13.MCASP1_AXR13_INPUTENABLE
  [17] MCASP5_AXR0_PULLTYPESELECT rw
    values as CTRL_CORE_PAD_MCASP1_AXR13.MCASP1_AXR13_PULLTYPESELECT
  [16] MCASP5_AXR0_PULLUDENABLE rw
    values as CTRL_CORE_PAD_MCASP1_AXR13.MCASP1_AXR13_PULLUDENABLE
  [8] MCASP5_AXR0_MODESELECT rw — Selects between the Default IO Timing Mode and a Virtual or Manual IO Timing Mode. Refer to the device Data Manual for definition of the required settings for a given mode of operation. When this bit is 0b1, a Virtual IO Timing Mode can be selected via the DELAYMODE field of this register, as described in, Virtual IO Timing Modes. Manual IO Timing Modes are selected via the procedure described in , Manual IO Timing Modes.
    values as CTRL_CORE_PAD_MCASP1_AXR13.MCASP1_AXR13_MODESELECT
  [7:4] MCASP5_AXR0_DELAYMODE rw — This bit field selects the Virtual Timing Mode used when the MODESELECT bit is set to 0b1. See, Virtual IO Timing Modes for details.
  [3:0] MCASP5_AXR0_MUXMODE rw
    0=MCASP5_AXR0; 2=SPI4_D0; 3=UART9_CTSN; 4=UART3_RXD; 6=VOUT2_D22; 8=VIN4A_D22; 9=VIN5A_D9; 11=PR2_MDIO_MDCLK; 12=PR2_PRU1_GPI3; 13=PR2_PRU1_GPO3; 15=DRIVER OFF
0x1750 CTRL_CORE_PAD_MCASP5_AXR1 reset 0x4000F
  [25] MCASP5_AXR1_WAKEUPEVENT ro
    values as CTRL_CORE_PAD_MCASP1_AXR13.MCASP1_AXR13_WAKEUPEVENT
  [24] MCASP5_AXR1_WAKEUPENABLE rw
    0=DISABLE (Wakeup is disabled); 1=ENABLE (Wakeup is enabled)
  [19] MCASP5_AXR1_SLEWCONTROL rw
    values as CTRL_CORE_PAD_MCASP1_AXR13.MCASP1_AXR13_SLEWCONTROL
  [18] MCASP5_AXR1_INPUTENABLE rw
    values as CTRL_CORE_PAD_MCASP1_AXR13.MCASP1_AXR13_INPUTENABLE
  [17] MCASP5_AXR1_PULLTYPESELECT rw
    values as CTRL_CORE_PAD_MCASP1_AXR13.MCASP1_AXR13_PULLTYPESELECT
  [16] MCASP5_AXR1_PULLUDENABLE rw
    values as CTRL_CORE_PAD_MCASP1_AXR13.MCASP1_AXR13_PULLUDENABLE
  [8] MCASP5_AXR1_MODESELECT rw — Selects between the Default IO Timing Mode and a Virtual or Manual IO Timing Mode. Refer to the device Data Manual for definition of the required settings for a given mode of operation. When this bit is 0b1, a Virtual IO Timing Mode can be selected via the DELAYMODE field of this register, as described in, Virtual IO Timing Modes. Manual IO Timing Modes are selected via the procedure described in , Manual IO Timing Modes.
    values as CTRL_CORE_PAD_MCASP1_AXR13.MCASP1_AXR13_MODESELECT
  [7:4] MCASP5_AXR1_DELAYMODE rw — This bit field selects the Virtual Timing Mode used when the MODESELECT bit is set to 0b1. See, Virtual IO Timing Modes for details.
  [3:0] MCASP5_AXR1_MUXMODE rw
    0=MCASP5_AXR1; 2=SPI4_CS0; 3=UART9_RTSN; 4=UART3_TXD; 6=VOUT2_D23; 8=VIN4A_D23; 9=VIN5A_D8; 11=PR2_MDIO_DATA; 12=PR2_PRU1_GPI4; 13=PR2_PRU1_GPO4; 15=DRIVER OFF
0x1754 CTRL_CORE_PAD_MMC1_CLK reset 0x6000F
  [25] MMC1_CLK_WAKEUPEVENT ro
    values as CTRL_CORE_PAD_MCASP1_AXR13.MCASP1_AXR13_WAKEUPEVENT
  [24] MMC1_CLK_WAKEUPENABLE rw
    0=DISABLE (Wakeup is disabled); 1=ENABLE (Wakeup is enabled)
  [18] MMC1_CLK_ACTIVE rw — Controls enabling/disabling of the input buffer. 0x0: Input buffer is disabled 0x1: Input buffer is enabled
  [17] MMC1_CLK_PULLTYPESELECT rw
    values as CTRL_CORE_PAD_MCASP1_AXR13.MCASP1_AXR13_PULLTYPESELECT
  [16] MMC1_CLK_PULLUDENABLE rw
    values as CTRL_CORE_PAD_MCASP1_AXR13.MCASP1_AXR13_PULLUDENABLE
  [8] MMC1_CLK_MODESELECT rw — Selects between the Default IO Timing Mode and a Virtual or Manual IO Timing Mode. Refer to the device Data Manual for definition of the required settings for a given mode of operation. When this bit is 0b1, a Virtual IO Timing Mode can be selected via the DELAYMODE field of this register, as described in, Virtual IO Timing Modes. Manual IO Timing Modes are selected via the procedure described in , Manual IO Timing Modes.
    values as CTRL_CORE_PAD_MCASP1_AXR13.MCASP1_AXR13_MODESELECT
  [7:4] MMC1_CLK_DELAYMODE rw — This bit field selects the Virtual Timing Mode used when the MODESELECT bit is set to 0b1. See, Virtual IO Timing Modes for details.
  [3:0] MMC1_CLK_MUXMODE rw
    0=MMC1_CLK; 14=GPIO6_21; 15=DRIVER OFF
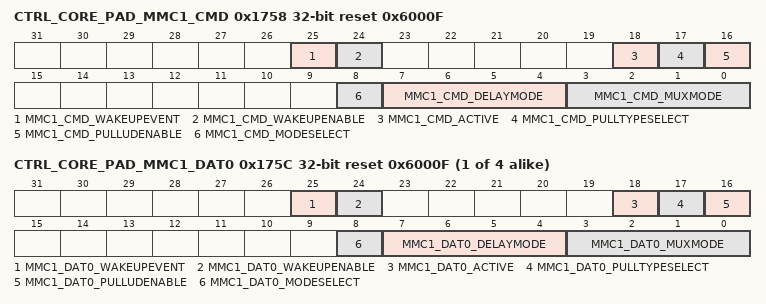
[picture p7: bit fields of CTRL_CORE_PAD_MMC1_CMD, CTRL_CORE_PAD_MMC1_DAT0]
0x1758 CTRL_CORE_PAD_MMC1_CMD reset 0x6000F
  [25] MMC1_CMD_WAKEUPEVENT ro
    values as CTRL_CORE_PAD_MCASP1_AXR13.MCASP1_AXR13_WAKEUPEVENT
  [24] MMC1_CMD_WAKEUPENABLE rw
    0=DISABLE (Wakeup is disabled); 1=ENABLE (Wakeup is enabled)
  [18] MMC1_CMD_ACTIVE rw — Controls enabling/disabling of the input buffer. 0x0: Input buffer is disabled 0x1: Input buffer is enabled
  [17] MMC1_CMD_PULLTYPESELECT rw
    values as CTRL_CORE_PAD_MCASP1_AXR13.MCASP1_AXR13_PULLTYPESELECT
  [16] MMC1_CMD_PULLUDENABLE rw
    values as CTRL_CORE_PAD_MCASP1_AXR13.MCASP1_AXR13_PULLUDENABLE
  [8] MMC1_CMD_MODESELECT rw — Selects between the Default IO Timing Mode and a Virtual or Manual IO Timing Mode. Refer to the device Data Manual for definition of the required settings for a given mode of operation. When this bit is 0b1, a Virtual IO Timing Mode can be selected via the DELAYMODE field of this register, as described in, Virtual IO Timing Modes. Manual IO Timing Modes are selected via the procedure described in , Manual IO Timing Modes.
    values as CTRL_CORE_PAD_MCASP1_AXR13.MCASP1_AXR13_MODESELECT
  [7:4] MMC1_CMD_DELAYMODE rw — This bit field selects the Virtual Timing Mode used when the MODESELECT bit is set to 0b1. See, Virtual IO Timing Modes for details.
  [3:0] MMC1_CMD_MUXMODE rw
    0=MMC1_CMD; 14=GPIO6_22; 15=DRIVER OFF
{0x175C+4i} CTRL_CORE_PAD_MMC1_DAT{i} reset 0x6000F (i=0..3)
  [25] MMC1_DAT{i}_WAKEUPEVENT ro
    values as CTRL_CORE_PAD_MCASP1_AXR13.MCASP1_AXR13_WAKEUPEVENT
  [24] MMC1_DAT{i}_WAKEUPENABLE rw
    0=DISABLE (Wakeup is disabled); 1=ENABLE (Wakeup is enabled)
  [18] MMC1_DAT{i}_ACTIVE rw — Controls enabling/disabling of the input buffer. 0x0: Input buffer is disabled 0x1: Input buffer is enabled
  [17] MMC1_DAT{i}_PULLTYPESELECT rw
    values as CTRL_CORE_PAD_MCASP1_AXR13.MCASP1_AXR13_PULLTYPESELECT
  [16] MMC1_DAT{i}_PULLUDENABLE rw
    values as CTRL_CORE_PAD_MCASP1_AXR13.MCASP1_AXR13_PULLUDENABLE
  [8] MMC1_DAT{i}_MODESELECT rw — Selects between the Default IO Timing Mode and a Virtual or Manual IO Timing Mode. Refer to the device Data Manual for definition of the required settings for a given mode of operation. When this bit is 0b1, a Virtual IO Timing Mode can be selected via the DELAYMODE field of this register, as described in, Virtual IO Timing Modes. Manual IO Timing Modes are selected via the procedure described in , Manual IO Timing Modes.
    values as CTRL_CORE_PAD_MCASP1_AXR13.MCASP1_AXR13_MODESELECT
  [7:4] MMC1_DAT{i}_DELAYMODE rw — This bit field selects the Virtual Timing Mode used when the MODESELECT bit is set to 0b1. See, Virtual IO Timing Modes for details.
  [3:0] MMC1_DAT{i}_MUXMODE rw
    0=MMC1_DAT{i}; 14=GPIO6_{i+23}; 15=DRIVER OFF
